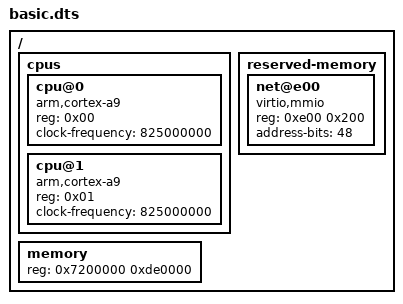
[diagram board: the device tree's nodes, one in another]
/dts-v1/;

/ {

	cpus {
		#address-cells = <0x01>;
		#size-cells = <0x00>;

		cpu@0 {
			device_type = "cpu";
			compatible = "arm,cortex-a9";
			reg = <0x00>;
            clock-frequency = <825000000>;
		};

		cpu@1 {
			device_type = "cpu";
			compatible = "arm,cortex-a9";
			reg = <0x01>;
            clock-frequency = <825000000>;
		};
	};

	memory {
		device_type = "memory";
		reg = <0x7200000 0xde0000>;
	};

	reserved-memory {
		#address-cells = <0x01>;
		#size-cells = <0x01>;
		ranges = <0x00 0x1000 0xc0000000>;

		net@e00 {
			compatible = "virtio,mmio";
			reg = <0xe00 0x200>;
            address-bits = <48>;
		};
	};
};
